# npcx9m6f register map
Registers are 8-bit, read-write, no defined reset value unless marked. A register's access mark holds for its fields unless they carry their own. Offsets are from the block's base; [hi:lo] are bit positions; {n}, {i} and the like mark numbered series.

## GPIO2 — GENERAL-PURPOSE I/O
Base 0x40085000
0x00 P2DOUT
0x01 P2DIN
0x02 P2DIR
0x03 P2PULL
0x04 P2PUD
0x05 P2ENVDD
0x06 P2OTYPE

## GPIO3 — GENERAL-PURPOSE I/O
Base 0x40087000
0x00 P3DOUT
0x01 P3DIN
0x02 P3DIR
0x03 P3PULL
0x04 P3PUD
0x05 P3ENVDD
0x06 P3OTYPE

## GPIO4 — GENERAL-PURPOSE I/O
Base 0x40089000
0x00 P4DOUT
0x01 P4DIN
0x02 P4DIR
0x03 P4PULL
0x04 P4PUD
0x05 P4ENVDD
0x06 P4OTYPE

## GPIO5 — GENERAL-PURPOSE I/O
Base 0x4008B000
0x00 P5DOUT
0x01 P5DIN
0x02 P5DIR
0x03 P5PULL
0x04 P5PUD
0x05 P5ENVDD
0x06 P5OTYPE

## GPIO6 — GENERAL-PURPOSE I/O
Base 0x4008D000
0x00 P6DOUT
0x01 P6DIN
0x02 P6DIR
0x03 P6PULL
0x04 P6PUD
0x05 P6ENVDD
0x06 P6OTYPE

## GPIO7 — GENERAL-PURPOSE I/O
Base 0x4008F000
0x00 P7DOUT
0x01 P7DIN
0x02 P7DIR
0x03 P7PULL
0x04 P7PUD
0x05 P7ENVDD
0x06 P7OTYPE

## GPIO8 — GENERAL-PURPOSE I/O
Base 0x40091000
0x00 P8DOUT
0x01 P8DIN
0x02 P8DIR
0x03 P8PULL
0x04 P8PUD
0x05 P8ENVDD
0x06 P8OTYPE

## GPIO9 — GENERAL-PURPOSE I/O
Base 0x40093000
0x00 P9DOUT
0x01 P9DIN
0x02 P9DIR
0x03 P9PULL
0x04 P9PUD
0x05 P9ENVDD
0x06 P9OTYPE

## GPIOA — GENERAL-PURPOSE I/O
Base 0x40095000
0x00 PADOUT
0x01 PADIN
0x02 PADIR
0x03 PAPULL
0x04 PAPUD
0x05 PAENVDD
0x06 PAOTYPE

## GPIOB — GENERAL-PURPOSE I/O
Base 0x40097000
Same registers: GPIOC 0x40099000, GPIOD 0x4009B000, GPIOE 0x4009D000, GPIOF 0x4009F000, GPIOG 0x400A7000, GPIOH 0x400A9000, GPIO_STBY_0 0x400AB000, GPIO_STBY_1 0x400AD000
0x00 PBDOUT
0x01 PBDIN
0x02 PBDIR
0x03 PBPULL
0x04 PBPUD
0x05 PBENVDD
0x06 PBOTYPE

## SMB1 — SMBus-Interface 1
Base 0x40009000
Same registers: SMB2 0x4000B000, SMB3 0x400C0000, SMB4 0x400C2000, SMB5 0x400C6000, SMB6 0x400C8000
0x00 SMBnSDA
  [7:0] SMB_DAT
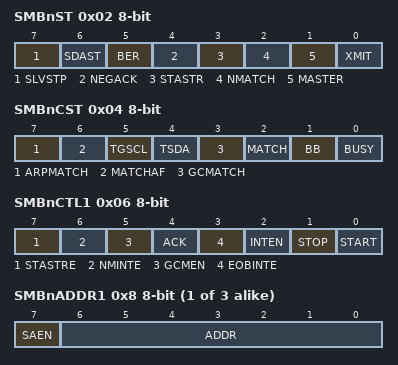
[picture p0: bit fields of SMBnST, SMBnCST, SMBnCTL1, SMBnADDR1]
0x02 SMBnST
  [7] SLVSTP, [6] SDAST, [5] BER, [4] NEGACK, [3] STASTR, [2] NMATCH, [1] MASTER, [0] XMIT
0x04 SMBnCST
  [7] ARPMATCH, [6] MATCHAF, [5] TGSCL, [4] TSDA, [3] GCMATCH, [2] MATCH, [1] BB, [0] BUSY
0x06 SMBnCTL1
  [7] STASTRE, [6] NMINTE, [5] GCMEN, [4] ACK, [3] EOBINTE, [2] INTEN, [1] STOP, [0] START
{0x4+4i} SMBnADDR{i} (i=1..3)
  [7] SAEN, [6:0] ADDR
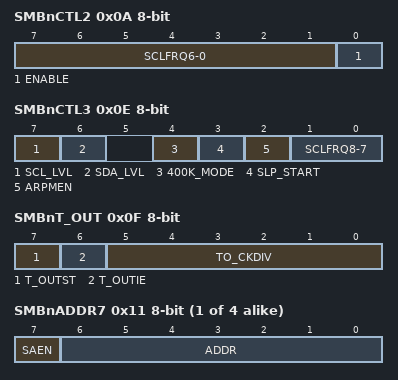
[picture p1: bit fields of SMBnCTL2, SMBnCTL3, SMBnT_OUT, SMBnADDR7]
0x0A SMBnCTL2
  [7:1] SCLFRQ6-0, [0] ENABLE
0x0E SMBnCTL3
  [7] SCL_LVL, [6] SDA_LVL, [4] 400K_MODE, [3] SLP_START, [2] ARPMEN, [1:0] SCLFRQ8-7
0x0F SMBnT_OUT
  [7] T_OUTST, [6] T_OUTIE, [5:0] TO_CKDIV
{0x3+2i} SMBnADDR{i} (i=7..10)
  [7] SAEN, [6:0] ADDR
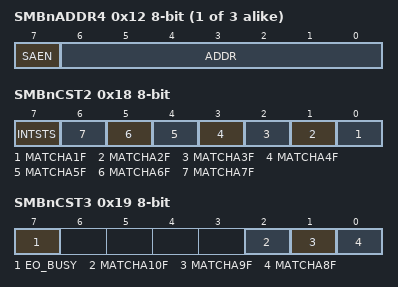
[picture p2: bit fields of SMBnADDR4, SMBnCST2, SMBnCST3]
{0xA+2i} SMBnADDR{i} (i=4..6)
  [7] SAEN, [6:0] ADDR
0x18 SMBnCST2
  [7] INTSTS, [n-1] MATCHA{n}F (n=1..7)
0x19 SMBnCST3
  [7] EO_BUSY, [2] MATCHA10F, [1] MATCHA9F, [0] MATCHA8F
0x1A SMBnCTL4
  [5:0] HLDT
0x1B SMBnCTL5
  [3:0] DBNCT
0x1C SMBnSCLLT
  [7:0] SCLLT7-0
0x1E SMBnSCLHT
  [7:0] SCLHT7-0

## PS2
Base 0x400B1000
0x00 PSDAT
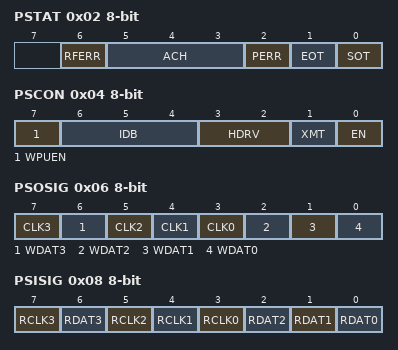
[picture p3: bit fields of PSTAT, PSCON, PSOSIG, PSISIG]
0x02 PSTAT
  [6] RFERR, [5:3] ACH, [2] PERR, [1] EOT, [0] SOT
0x04 PSCON
  [7] WPUEN, [6:4] IDB, [3:2] HDRV, [1] XMT, [0] EN
0x06 PSOSIG
  [7] CLK3, [6] WDAT3, [5] CLK2, [4] CLK1, [3] CLK0, [2] WDAT2, [1] WDAT1, [0] WDAT0
0x08 PSISIG
  [7] RCLK3, [6] RDAT3, [5] RCLK2, [4] RCLK1, [3] RCLK0, [2] RDAT2, [1] RDAT1, [0] RDAT0
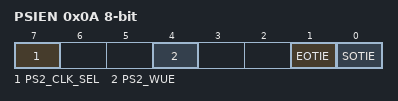
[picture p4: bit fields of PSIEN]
0x0A PSIEN
  [7] PS2_CLK_SEL, [4] PS2_WUE, [1] EOTIE, [0] SOTIE
0x0E PS2_VER

## LCT — LONG COUNTDOWN TIMER
Base 0x400DD000
0x00 LCTVER
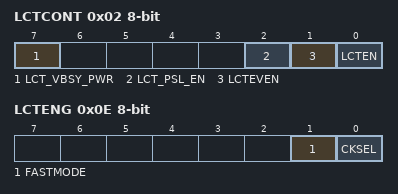
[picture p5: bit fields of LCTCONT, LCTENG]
0x02 LCTCONT
  [7] LCT_VBSY_PWR, [2] LCT_PSL_EN, [1] LCTEVEN, [0] LCTEN
0x04 LCTSTAT
  [0] LCTEVST
0x05 LCTSECOND
0x06 LCTMINUT
0x08 LCTHOUR
  [4:0] HOURS
0x0A LCTDAY
  [4:0] DAYS
0x0C LCTWEEK
  [3:0] WEEKS
0x0E LCTENG
  [1] FASTMODE, [0] CKSEL

## MTC — MONOTONIC COUNTER
Base 0x400B7000
0x00 TTC 32-bit
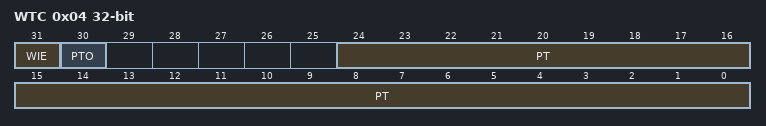
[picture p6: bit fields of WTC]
0x04 WTC 32-bit
  [31] WIE, [30] PTO, [24:0] PT
0x08 MTCTST
  [0] MTFEN

## TWD — TIMER AND WATCHDOG
Base 0x400D8000
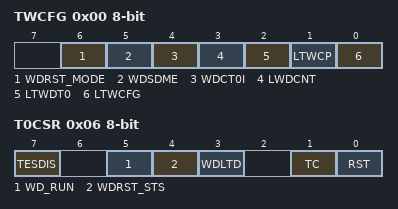
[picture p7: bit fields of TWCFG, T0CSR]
0x00 TWCFG
  [6] WDRST_MODE, [5] WDSDME, [4] WDCT0I, [3] LWDCNT, [2] LTWDT0, [1] LTWCP, [0] LTWCFG
0x02 TWCP
0x04 TWDT0 16-bit
0x06 T0CSR
  [7] TESDIS, [5] WD_RUN, [4] WDRST_STS, [3] WDLTD, [1] TC, [0] RST
0x08 WDCNT
0x0A WDSDM
0x0C TWMT0 16-bit
0x0E TWMWD
0x10 WDCP
